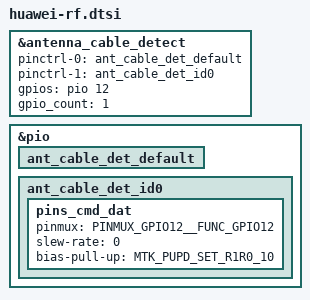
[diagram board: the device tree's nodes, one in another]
&antenna_cable_detect {
	pinctrl-names = "default", "id0";
	pinctrl-0 = <&ant_cable_det_default>;
	pinctrl-1 = <&ant_cable_det_id0>;
	gpios = <&pio 12 0 >;
	gpio_count = <1>;
};

&pio {
	ant_cable_det_default: ant_cable_det_default {
	};

	ant_cable_det_id0: ant_cable_det_id0 {
		pins_cmd_dat {
			pinmux = <PINMUX_GPIO12__FUNC_GPIO12>;
			slew-rate = <0>;
			bias-pull-up = <MTK_PUPD_SET_R1R0_10>;
		};
	};
};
